# XMC4300 register map
Vendor: Infineon; File version: 1.0.4 (Reference Manual v1.0)
CPU: CM4 r2p0, little endian, MPU, FPU, 6 interrupt priority bits
Registers are 32-bit, read-write, reset 0x0 unless marked. A register's access mark holds for its fields unless they carry their own. Offsets are from the block's base; [hi:lo] are bit positions.

## SCU_RESET — System Control Unit
Base 0x50004400
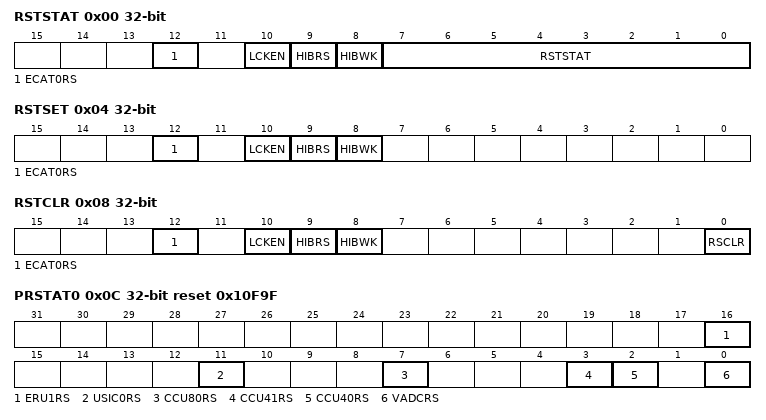
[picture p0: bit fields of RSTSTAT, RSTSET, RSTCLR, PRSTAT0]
0x00 RSTSTAT ro (reset mask 0xFFFF0000) — RCU Reset Status
  [12] ECAT0RS — ECAT0 Reset Status Information
    0=Const_0 (Reset did not occur); 1=Const_1 (Reset occurred)
  [10] LCKEN — Enable Lockup Status
    0=Const_0 (Reset by Lockup disabled); 1=Const_1 (Reset by Lockup enabled)
  [9] HIBRS — Hibernate Reset Status
    0=Const_0 (Reset de-asserted); 1=Const_1 (Reset asserted)
  [8] HIBWK — Hibernate Wake-up Status
    0=Const_0 (No Wake-up); 1=Const_1 (Wake-up event)
  [7:0] RSTSTAT — Reset Status Information
    1=Const_00000001 (PORST reset); 2=Const_00000010 (SWD reset); 4=Const_00000100 (PV reset); 8=Const_00001000 (CPU system reset); 16=Const_00010000 (CPU lockup reset); 32=Const_00100000 (WDT reset); 128=Const_10000000 (Parity Error reset)
0x04 RSTSET wo — RCU Reset Set Register
  [12] ECAT0RS — ECAT0 Reset Status Information
    0=Const_0 (No effect); 1=Const_1 (Assert reset status bit)
  [10] LCKEN — Enable Lockup Reset
    0=Const_0 (No effect); 1=Const_1 (Enable reset when Lockup gets asserted)
  [9] HIBRS — Set Hibernate Reset
    0=Const_0 (No effect); 1=Const_1 (Assert reset)
  [8] HIBWK — Set Hibernate Wake-up Reset Status
    0=Const_0 (No effect); 1=Const_1 (Assert reset status bit)
0x08 RSTCLR wo — RCU Reset Clear Register
  [12] ECAT0RS — ECAT0 Reset Status Information
    0=Const_0 (No effect); 1=Const_1 (De-assert reset status)
  [10] LCKEN — Enable Lockup Reset
    0=Const_0 (No effect); 1=Const_1 (Disable reset when Lockup gets asserted)
  [9] HIBRS — Clear Hibernate Reset
    0=Const_0 (No effect); 1=Const_1 (De-assert reset)
  [8] HIBWK — Clear Hibernate Wake-up Reset Status
    0=Const_0 (No effect); 1=Const_1 (De-assert reset status bit)
  [0] RSCLR — Clear Reset Status
    0=Const_0 (No effect); 1=Const_1 (Clears field RSTSTAT.RSTSTAT)
0x0C PRSTAT0 ro reset 0x10F9F — RCU Peripheral 0 Reset Status
  [all] fields
    0=Const_0 (Reset de-asserted); 1=Const_1 (Reset asserted)
  [16] ERU1RS — ERU1 Reset Status
  [11] USIC0RS — USIC0 Reset Status
  [7] CCU80RS — CCU80 Reset Status
  [3] CCU41RS — CCU41 Reset Status
  [2] CCU40RS — CCU40 Reset Status
  [0] VADCRS — VADC Reset Status
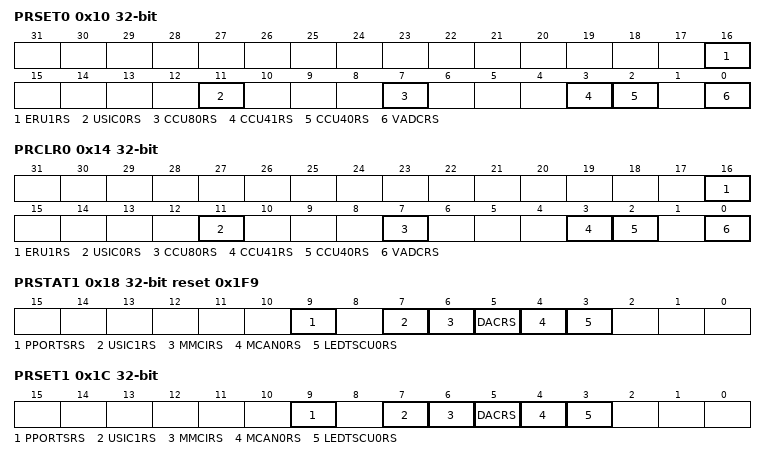
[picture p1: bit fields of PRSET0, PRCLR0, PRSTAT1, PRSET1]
0x10 PRSET0 wo — RCU Peripheral 0 Reset Set
  [all] fields
    0=Const_0 (No effect); 1=Const_1 (Assert reset)
  [16] ERU1RS — ERU1 Reset Assert
  [11] USIC0RS — USIC0 Reset Assert
  [7] CCU80RS — CCU80 Reset Assert
  [3] CCU41RS — CCU41 Reset Assert
  [2] CCU40RS — CCU40 Reset Assert
  [0] VADCRS — VADC Reset Assert
0x14 PRCLR0 wo — RCU Peripheral 0 Reset Clear
  [all] fields
    0=Const_0 (No effect); 1=Const_1 (De-assert reset)
  [16] ERU1RS — ERU1 Reset Clear
  [11] USIC0RS — USIC0 Reset Clear
  [7] CCU80RS — CCU80 Reset Clear
  [3] CCU41RS — CCU41 Reset Clear
  [2] CCU40RS — CCU40 Reset Clear
  [0] VADCRS — VADC Reset Clear
0x18 PRSTAT1 ro reset 0x1F9 — RCU Peripheral 1 Reset Status
  [all] fields
    0=Const_0 (Reset de-asserted); 1=Const_1 (Reset asserted)
  [9] PPORTSRS — PORTS Reset Status
  [7] USIC1RS — USIC1 Reset Status
  [6] MMCIRS — MMC Interface Reset Status
  [5] DACRS — DAC Reset Status
  [4] MCAN0RS — MultiCAN Reset Status
  [3] LEDTSCU0RS — LEDTS Reset Status
0x1C PRSET1 wo — RCU Peripheral 1 Reset Set
  [all] fields
    0=Const_0 (No effect); 1=Const_1 (Assert reset)
  [9] PPORTSRS — PORTS Reset Assert
  [7] USIC1RS — USIC1 Reset Assert
  [6] MMCIRS — MMC Interface Reset Assert
  [5] DACRS — DAC Reset Assert
  [4] MCAN0RS — MultiCAN Reset Assert
  [3] LEDTSCU0RS — LEDTS Reset Assert
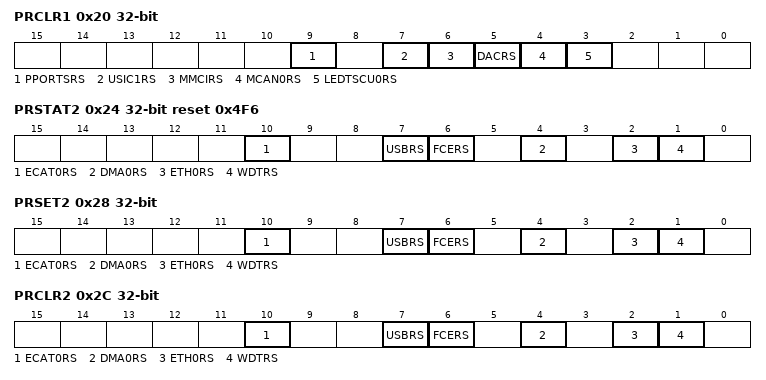
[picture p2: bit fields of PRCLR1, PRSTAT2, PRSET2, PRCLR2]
0x20 PRCLR1 wo — RCU Peripheral 1 Reset Clear
  [all] fields
    0=Const_0 (No effect); 1=Const_1 (De-assert reset)
  [9] PPORTSRS — PORTS Reset Clear
  [7] USIC1RS — USIC1 Reset Clear
  [6] MMCIRS — MMC Interface Reset Clear
  [5] DACRS — DAC Reset Clear
  [4] MCAN0RS — MultiCAN Reset Clear
  [3] LEDTSCU0RS — LEDTS Reset Clear
0x24 PRSTAT2 ro reset 0x4F6 — RCU Peripheral 2 Reset Status
  [all] fields
    0=Const_0 (Reset de-asserted); 1=Const_1 (Reset asserted)
  [10] ECAT0RS — ECAT0 Reset Status
  [7] USBRS — USB Reset Status
  [6] FCERS — FCE Reset Status
  [4] DMA0RS — DMA0 Reset Status
  [2] ETH0RS — ETH0 Reset Status
  [1] WDTRS — WDT Reset Status
0x28 PRSET2 wo — RCU Peripheral 2 Reset Set
  [all] fields
    0=Const_0 (No effect); 1=Const_1 (Assert reset)
  [10] ECAT0RS — ECAT0 Reset Assert
  [7] USBRS — USB Reset Assert
  [6] FCERS — FCE Reset Assert
  [4] DMA0RS — DMA0 Reset Assert
  [2] ETH0RS — ETH0 Reset Assert
  [1] WDTRS — WDT Reset Assert
0x2C PRCLR2 wo — RCU Peripheral 2 Reset Clear
  [all] fields
    0=Const_0 (No effect); 1=Const_1 (De-assert reset)
  [10] ECAT0RS — ECAT0 Reset Clear
  [7] USBRS — USB Reset Clear
  [6] FCERS — FCE Reset Clear
  [4] DMA0RS — DMA0 Reset Clear
  [2] ETH0RS — ETH0 Reset Clear
  [1] WDTRS — WDT Reset Clear
